# STM32F446 register map
File version: 1.9
CPU: CM4 r0p1, little endian, MPU, FPU, 4 interrupt priority bits
Registers are 32-bit, read-write, reset 0x0 unless marked. A register's access mark holds for its fields unless they carry their own. Offsets are from the block's base; [hi:lo] are bit positions.

## FMPI2C — Fast-mode Plus Inter-integrated circuit interface
Base 0x40006000
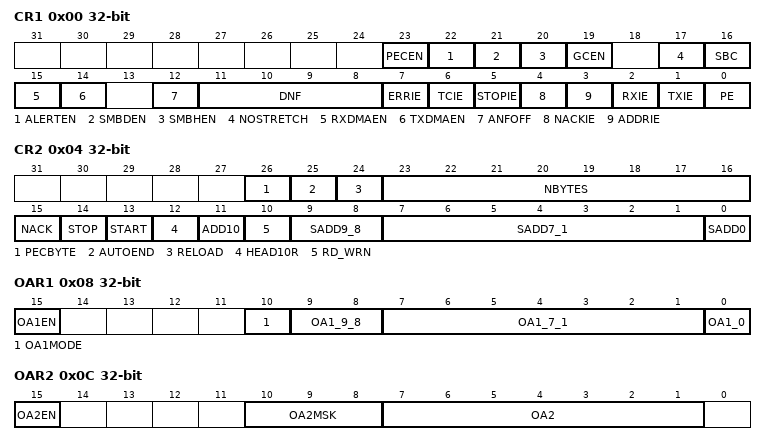
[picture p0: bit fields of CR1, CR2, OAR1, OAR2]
0x00 CR1 — Control register 1
  [23] PECEN — PEC enable
  [22] ALERTEN — SMBus alert enable
  [21] SMBDEN — SMBus Device Default address enable
  [20] SMBHEN — SMBus Host address enable
  [19] GCEN — General call enable
  [17] NOSTRETCH — Clock stretching disable
  [16] SBC — Slave byte control
  [15] RXDMAEN — DMA reception requests enable
  [14] TXDMAEN — DMA transmission requests enable
  [12] ANFOFF — Analog noise filter OFF
  [11:8] DNF — Digital noise filter
  [7] ERRIE — Error interrupts enable
  [6] TCIE — Transfer Complete interrupt enable
  [5] STOPIE — STOP detection Interrupt enable
  [4] NACKIE — Not acknowledge received Interrupt enable
  [3] ADDRIE — Address match Interrupt enable (slave only)
  [2] RXIE — RX Interrupt enable
  [1] TXIE — TX Interrupt enable
  [0] PE — Peripheral enable
0x04 CR2 — Control register 1
  [26] PECBYTE — Packet error checking byte
  [25] AUTOEND — Automatic end mode (master mode)
  [24] RELOAD — NBYTES reload mode
  [23:16] NBYTES — Number of bytes
  [15] NACK — NACK generation (slave mode)
  [14] STOP — Stop generation (master mode)
  [13] START — Start generation
  [12] HEAD10R — 10-bit address header only read direction (master receiver mode)
  [11] ADD10 — 10-bit addressing mode (master mode)
  [10] RD_WRN — Transfer direction (master mode)
  [9:8] SADD9_8 — Slave address bit 9:8 (master mode)
  [7:1] SADD7_1 — Slave address bit 7:1 (master mode)
  [0] SADD0 — Slave address bit 0 (master mode)
0x08 OAR1 — Own address 1 register
  [15] OA1EN — Own Address 1 enable
  [10] OA1MODE — Own Address 1 10-bit mode
  [9:8] OA1_9_8 — Interface address
  [7:1] OA1_7_1 — Interface address
  [0] OA1_0 — Interface address
0x0C OAR2 — Own address 2 register
  [15] OA2EN — Own Address 2 enable
  [10:8] OA2MSK — Own Address 2 masks
  [7:1] OA2 — Interface address
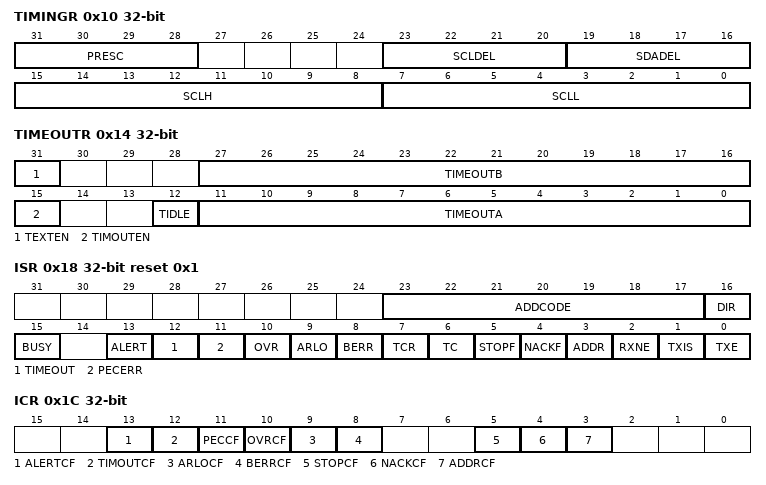
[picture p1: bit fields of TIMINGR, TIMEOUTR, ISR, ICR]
0x10 TIMINGR — Timing register
  [31:28] PRESC — Timing prescaler
  [23:20] SCLDEL — Data setup time
  [19:16] SDADEL — Data hold time
  [15:8] SCLH — SCL high period (master mode)
  [7:0] SCLL — SCL low period (master mode)
0x14 TIMEOUTR — Timeout register
  [31] TEXTEN — Extended clock timeout enable
  [27:16] TIMEOUTB — Bus timeout B
  [15] TIMOUTEN — Clock timeout enable
  [12] TIDLE — Idle clock timeout detection
  [11:0] TIMEOUTA — Bus Timeout A
0x18 ISR ro reset 0x1 — Interrupt and status register
  [23:17] ADDCODE — Address match code (Slave mode)
  [16] DIR — Transfer direction (Slave mode)
  [15] BUSY — Bus busy
  [13] ALERT — SMBus alert
  [12] TIMEOUT — Timeout or tLOW detection flag
  [11] PECERR — PEC Error in reception
  [10] OVR — Overrun/Underrun (slave mode)
  [9] ARLO — Arbitration lost
  [8] BERR — Bus error
  [7] TCR — Transfer Complete Reload
  [6] TC — Transfer Complete (master mode)
  [5] STOPF — Stop detection flag
  [4] NACKF — Not Acknowledge received flag
  [3] ADDR — Address matched (slave mode)
  [2] RXNE — Receive data register not empty (receivers)
  [1] TXIS — Transmit interrupt status (transmitters)
  [0] TXE — Transmit data register empty (transmitters)
0x1C ICR wo — Interrupt clear register
  [13] ALERTCF — Alert flag clear
  [12] TIMOUTCF — Timeout detection flag clear
  [11] PECCF — PEC Error flag clear
  [10] OVRCF — Overrun/Underrun flag clear
  [9] ARLOCF — Arbitration Lost flag clear
  [8] BERRCF — Bus error flag clear
  [5] STOPCF — Stop detection flag clear
  [4] NACKCF — Not Acknowledge flag clear
  [3] ADDRCF — Address matched flag clear
0x20 PECR ro — PEC register
  [7:0] PEC — Packet error checking register
0x24 RXDR ro — Receive data register
  [7:0] RXDATA — 8-bit receive data
0x28 TXDR ro — Transmit data register
  [7:0] TXDATA — 8-bit transmit data

## Notices in the file
Copyright (c) 2024 STMicroelectronics.
SPDX-License-Identifier: Apache-2.0
Licensed under the Apache License, Version 2.0 (the "License");
you may not use this file except in compliance with the License.
You may obtain a copy of the License at
http://www.apache.org/licenses/LICENSE-2.0
Unless required by applicable law or agreed to in writing, software
distributed under the License is distributed on an "AS IS" BASIS,
WITHOUT WARRANTIES OR CONDITIONS OF ANY KIND, either express or implied.
See the License for the specific language governing permissions and
limitations under the License.
